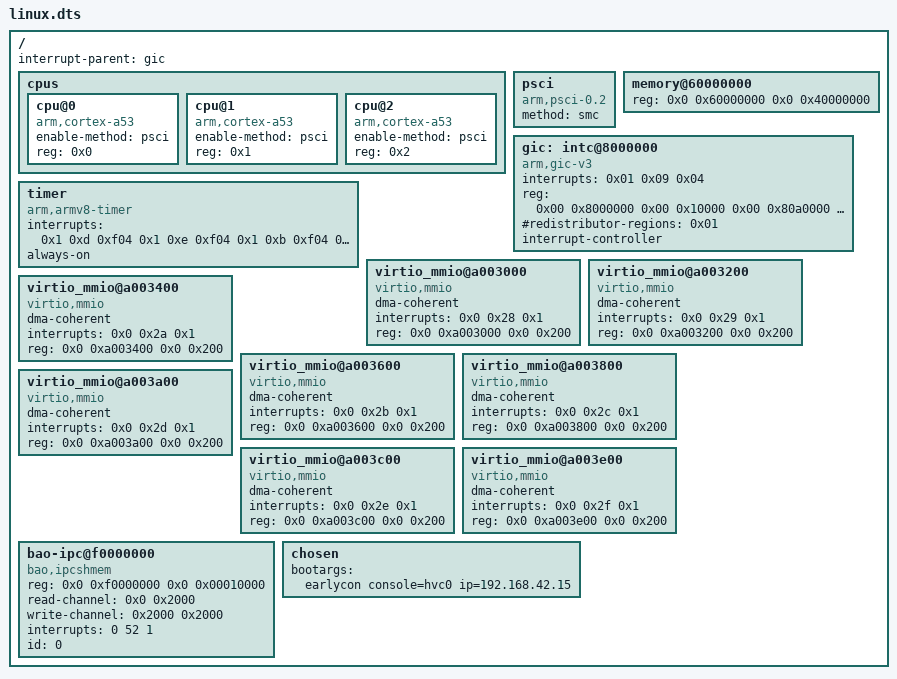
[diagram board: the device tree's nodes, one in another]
/dts-v1/;

/ {
	#size-cells = <0x2>;
	#address-cells = <0x2>;
	interrupt-parent = <&gic>;

	cpus {
		#size-cells = <0x0>;
		#address-cells = <0x1>;

		cpu@0 {
			compatible = "arm,cortex-a53", "arm,armv8";
			device_type = "cpu";
			enable-method = "psci";
			reg = <0x0>;
		};

		cpu@1 {
			compatible = "arm,cortex-a53", "arm,armv8";
			device_type = "cpu";
			enable-method = "psci";
			reg = <0x1>;
		};

		cpu@2 {
			compatible = "arm,cortex-a53", "arm,armv8";
			device_type = "cpu";
			enable-method = "psci";
			reg = <0x2>;
		};

	};

	psci {
		compatible = "arm,psci-0.2";
		method = "smc";
	};
	
	memory@60000000 {
		device_type = "memory";
		reg = <0x0 0x60000000 0x0 0x40000000>;
	};

    gic: intc@8000000 {
		interrupts = <0x01 0x09 0x04>;
		reg = <0x00 0x8000000 0x00 0x10000 0x00 0x80a0000 0x00 0xf60000>;
		#redistributor-regions = <0x01>;
		compatible = "arm,gic-v3";
		ranges;
		#size-cells = <0x02>;
		#address-cells = <0x02>;
		interrupt-controller;
		#interrupt-cells = <0x03>;
	};

	timer {
		interrupts = <0x1 0xd 0xf04 0x1 0xe 0xf04 0x1 0xb 0xf04 0x1 0xa 0xf04>;
		always-on;
		compatible = "arm,armv8-timer", "arm,armv7-timer";
	};

	virtio_mmio@a003000 {
		dma-coherent;
		interrupts = <0x0 0x28 0x1>;
		reg = <0x0 0xa003000 0x0 0x200>;
		compatible = "virtio,mmio";
	};

	virtio_mmio@a003200 {
		dma-coherent;
		interrupts = <0x0 0x29 0x1>;
		reg = <0x0 0xa003200 0x0 0x200>;
		compatible = "virtio,mmio";
	};

	virtio_mmio@a003400 {
		dma-coherent;
		interrupts = <0x0 0x2a 0x1>;
		reg = <0x0 0xa003400 0x0 0x200>;
		compatible = "virtio,mmio";
	};

	virtio_mmio@a003600 {
		dma-coherent;
		interrupts = <0x0 0x2b 0x1>;
		reg = <0x0 0xa003600 0x0 0x200>;
		compatible = "virtio,mmio";
	};

	virtio_mmio@a003800 {
		dma-coherent;
		interrupts = <0x0 0x2c 0x1>;
		reg = <0x0 0xa003800 0x0 0x200>;
		compatible = "virtio,mmio";
	};

	virtio_mmio@a003a00 {
		dma-coherent;
		interrupts = <0x0 0x2d 0x1>;
		reg = <0x0 0xa003a00 0x0 0x200>;
		compatible = "virtio,mmio";
	};

	virtio_mmio@a003c00 {
		dma-coherent;
		interrupts = <0x0 0x2e 0x1>;
		reg = <0x0 0xa003c00 0x0 0x200>;
		compatible = "virtio,mmio";
	};

	virtio_mmio@a003e00 {
		dma-coherent;
		interrupts = <0x0 0x2f 0x1>;
		reg = <0x0 0xa003e00 0x0 0x200>;
		compatible = "virtio,mmio";
	};

    bao-ipc@f0000000 {
        compatible = "bao,ipcshmem";
        reg = <0x0 0xf0000000 0x0 0x00010000>;
		read-channel = <0x0 0x2000>;
		write-channel = <0x2000 0x2000>;
        interrupts = <0 52 1>;
		id = <0>;
    };

	chosen {
        bootargs = "earlycon console=hvc0 ip=192.168.42.15";
	};

};
